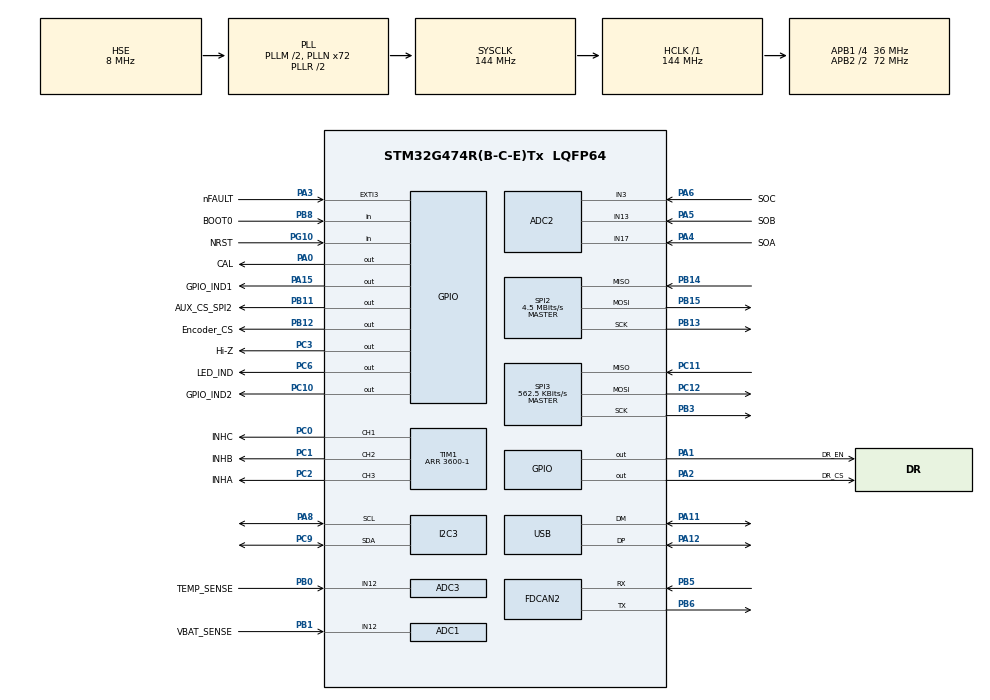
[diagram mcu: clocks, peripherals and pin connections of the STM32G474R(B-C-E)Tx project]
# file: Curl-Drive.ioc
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ADC1.Channel-1\#ChannelRegularConversion=ADC_CHANNEL_12
ADC1.ClockPrescaler=ADC_CLOCK_ASYNC_DIV4
ADC1.ContinuousConvMode=ENABLE
ADC1.DMAContinuousRequests=ENABLE
ADC1.NbrOfConversion=1
ADC1.NbrOfConversionFlag=1
ADC1.OffsetNumber-1\#ChannelRegularConversion=ADC_OFFSET_NONE
ADC1.Rank-1\#ChannelRegularConversion=1
ADC1.SamplingTime-1\#ChannelRegularConversion=ADC_SAMPLETIME_640CYCLES_5
ADC1.master=1
ADC2.ClockPrescaler=ADC_CLOCK_ASYNC_DIV4
ADC2.EnableInjectedConversion=ENABLE
ADC2.EnableRegularConversion=DISABLE
ADC2.ExternalTrigInjecConv=ADC_EXTERNALTRIGINJEC_T1_TRGO2
ADC2.ExternalTrigInjecConvEdge=ADC_EXTERNALTRIGINJECCONV_EDGE_FALLING
ADC2.InjNumberOfConversion=3
ADC2.InjectedChannel-1\#ChannelInjectedConversion=ADC_CHANNEL_17
ADC2.InjectedChannel-2\#ChannelInjectedConversion=ADC_CHANNEL_13
ADC2.InjectedChannel-3\#ChannelInjectedConversion=ADC_CHANNEL_3
ADC2.InjectedOffsetNumber-1\#ChannelInjectedConversion=ADC_OFFSET_NONE
ADC2.InjectedOffsetNumber-2\#ChannelInjectedConversion=ADC_OFFSET_NONE
ADC2.InjectedOffsetNumber-3\#ChannelInjectedConversion=ADC_OFFSET_NONE
ADC2.InjectedRank-1\#ChannelInjectedConversion=1
ADC2.InjectedRank-2\#ChannelInjectedConversion=2
ADC2.InjectedRank-3\#ChannelInjectedConversion=3
ADC2.InjectedSamplingTime-1\#ChannelInjectedConversion=ADC_SAMPLETIME_24CYCLES_5
ADC2.InjectedSamplingTime-2\#ChannelInjectedConversion=ADC_SAMPLETIME_24CYCLES_5
ADC2.InjectedSamplingTime-3\#ChannelInjectedConversion=ADC_SAMPLETIME_24CYCLES_5
ADC2.Rank1_Channel=ADC_CHANNEL_17
ADC2.Rank2_Channel=ADC_CHANNEL_13
ADC2.Rank3_Channel=ADC_CHANNEL_3
ADC3.Channel-0\#ChannelRegularConversion=ADC_CHANNEL_12
ADC3.ClockPrescaler=ADC_CLOCK_ASYNC_DIV4
ADC3.ContinuousConvMode=ENABLE
ADC3.DMAContinuousRequests=ENABLE
ADC3.NbrOfConversionFlag=1
ADC3.OffsetNumber-0\#ChannelRegularConversion=ADC_OFFSET_NONE
ADC3.Rank-0\#ChannelRegularConversion=1
ADC3.SamplingTime-0\#ChannelRegularConversion=ADC_SAMPLETIME_640CYCLES_5
ADC3.master=1
Dma.ADC1.0.Direction=DMA_PERIPH_TO_MEMORY
Dma.ADC1.0.EventEnable=DISABLE
Dma.ADC1.0.Instance=DMA1_Channel1
Dma.ADC1.0.MemDataAlignment=DMA_MDATAALIGN_HALFWORD
Dma.ADC1.0.MemInc=DMA_MINC_DISABLE
Dma.ADC1.0.Mode=DMA_CIRCULAR
Dma.ADC1.0.PeriphDataAlignment=DMA_PDATAALIGN_HALFWORD
Dma.ADC1.0.PeriphInc=DMA_PINC_DISABLE
Dma.ADC1.0.Polarity=HAL_DMAMUX_REQ_GEN_RISING
Dma.ADC1.0.Priority=DMA_PRIORITY_LOW
Dma.ADC1.0.RequestNumber=1
Dma.ADC1.0.SignalID=NONE
Dma.ADC1.0.SyncEnable=DISABLE
Dma.ADC1.0.SyncPolarity=HAL_DMAMUX_SYNC_NO_EVENT
Dma.ADC1.0.SyncRequestNumber=1
Dma.ADC1.0.SyncSignalID=NONE
Dma.ADC3.1.Direction=DMA_PERIPH_TO_MEMORY
Dma.ADC3.1.EventEnable=DISABLE
Dma.ADC3.1.Instance=DMA1_Channel2
Dma.ADC3.1.MemDataAlignment=DMA_MDATAALIGN_HALFWORD
Dma.ADC3.1.MemInc=DMA_MINC_DISABLE
Dma.ADC3.1.Mode=DMA_CIRCULAR
Dma.ADC3.1.PeriphDataAlignment=DMA_PDATAALIGN_HALFWORD
Dma.ADC3.1.PeriphInc=DMA_PINC_DISABLE
Dma.ADC3.1.Polarity=HAL_DMAMUX_REQ_GEN_RISING
Dma.ADC3.1.Priority=DMA_PRIORITY_LOW
Dma.ADC3.1.RequestNumber=1
Dma.ADC3.1.SignalID=NONE
Dma.ADC3.1.SyncEnable=DISABLE
Dma.ADC3.1.SyncPolarity=HAL_DMAMUX_SYNC_NO_EVENT
Dma.ADC3.1.SyncRequestNumber=1
Dma.ADC3.1.SyncSignalID=NONE
Dma.Request0=ADC1
Dma.Request1=ADC3
FDCAN2.AutoRetransmission=ENABLE
FDCAN2.CalculateBaudRateNominal=500000
FDCAN2.CalculateTimeBitNominal=2000
FDCAN2.CalculateTimeQuantumNominal=20.833333333333332
FDCAN2.DataTimeSeg1=13
FDCAN2.DataTimeSeg2=10
FDCAN2.FrameFormat=FDCAN_FRAME_FD_BRS
FDCAN2.NominalPrescaler=1
FDCAN2.NominalSyncJumpWidth=19
FDCAN2.NominalTimeSeg1=76
FDCAN2.NominalTimeSeg2=19
FDCAN2.ProtocolException=ENABLE
FDCAN2.StdFiltersNbr=1
I2C3.Timing=0x60715075
Mcu.Family=STM32G4
Mcu.Name=STM32G474R(B-C-E)Tx
Mcu.Package=LQFP64
NVIC.ADC1_2_IRQn=true\:0\:0\:false\:false\:true\:true\:true\:true
NVIC.DMA1_Channel1_IRQn=true\:0\:0\:false\:false\:true\:false\:true\:true
NVIC.DMA1_Channel2_IRQn=true\:0\:0\:false\:false\:true\:false\:true\:true
NVIC.EXTI3_IRQn=true\:0\:0\:false\:false\:true\:true\:true\:true
NVIC.FDCAN2_IT0_IRQn=true\:0\:0\:false\:false\:true\:true\:true\:true
NVIC.PriorityGroup=NVIC_PRIORITYGROUP_4
NVIC.TIM3_IRQn=true\:0\:0\:false\:false\:true\:true\:true\:true
NVIC.TIM6_DAC_IRQn=true\:0\:0\:false\:false\:true\:true\:true\:true
NVIC.TIM7_DAC_IRQn=true\:0\:0\:false\:false\:true\:true\:true\:true
NVIC.USB_LP_IRQn=true\:0\:0\:false\:false\:true\:false\:true\:true
PA0.GPIO_Label=CAL
PA0.Signal=GPIO_Output
PA1.GPIO_Label=DR_EN
PA1.Signal=GPIO_Output
PA11.Mode=Device
PA11.Signal=USB_DM
PA12.Mode=Device
PA12.Signal=USB_DP
PA13.Mode=Serial_Wire
PA13.Signal=SYS_JTMS-SWDIO
PA14.Mode=Serial_Wire
PA14.Signal=SYS_JTCK-SWCLK
PA15.GPIO_Label=GPIO_IND1
PA15.Signal=GPIO_Output
PA2.GPIO_Label=DR_CS
PA2.Signal=GPIO_Output
PA3.GPIO_Label=nFAULT
PA3.GPIO_ModeDefaultEXTI=GPIO_MODE_IT_FALLING
PA3.GPIO_PuPd=GPIO_PULLUP
PA3.Signal=GPXTI3
PA4.GPIO_Label=SOA
PA4.Mode=IN17-Single-Ended
PA4.Signal=ADC2_IN17
PA5.GPIO_Label=SOB
PA5.Mode=IN13-Single-Ended
PA5.Signal=ADC2_IN13
PA6.GPIO_Label=SOC
PA6.Mode=IN3-Single-Ended
PA6.Signal=ADC2_IN3
PA8.Mode=I2C
PA8.Signal=I2C3_SCL
PB0.GPIO_Label=TEMP_SENSE
PB0.Mode=IN12-Single-Ended
PB0.Signal=ADC3_IN12
PB1.GPIO_Label=VBAT_SENSE
PB1.Mode=IN12-Single-Ended
PB1.Signal=ADC1_IN12
PB11.GPIO_Label=AUX_CS_SPI2
PB11.Signal=GPIO_Output
PB12.GPIO_Label=Encoder_CS
PB12.Signal=GPIO_Output
PB13.Mode=Full_Duplex_Master
PB13.Signal=SPI2_SCK
PB14.Mode=Full_Duplex_Master
PB14.Signal=SPI2_MISO
PB15.Mode=Full_Duplex_Master
PB15.Signal=SPI2_MOSI
PB3.Mode=Full_Duplex_Master
PB3.Signal=SPI3_SCK
PB5.GPIO_Speed=GPIO_SPEED_FREQ_VERY_HIGH
PB5.Mode=FDCAN_Activate
PB5.Signal=FDCAN2_RX
PB6.GPIO_FM6=SYSCFG_FASTMODEPLUS_PB6
PB6.GPIO_Speed=GPIO_SPEED_FREQ_VERY_HIGH
PB6.Mode=FDCAN_Activate
PB6.Signal=FDCAN2_TX
PB8-BOOT0.GPIO_Label=BOOT0
PB8-BOOT0.Signal=GPIO_Input
PC0.GPIO_Label=INHC
PC0.Signal=S_TIM1_CH1
PC1.GPIO_Label=INHB
PC1.Signal=S_TIM1_CH2
PC10.GPIO_Label=GPIO_IND2
PC10.Signal=GPIO_Output
PC11.GPIO_PuPd=GPIO_PULLUP
PC11.Mode=Full_Duplex_Master
PC11.Signal=SPI3_MISO
PC12.Mode=Full_Duplex_Master
PC12.Signal=SPI3_MOSI
PC2.GPIO_Label=INHA
PC2.Signal=S_TIM1_CH3
PC3.GPIO_Label=Hi-Z
PC3.GPIO_PuPd=GPIO_PULLUP
PC3.Signal=GPIO_Output
PC6.GPIO_Label=LED_IND
PC6.Signal=GPIO_Output
PC9.Mode=I2C
PC9.Signal=I2C3_SDA
PF0-OSC_IN.Mode=HSE-External-Oscillator
PF0-OSC_IN.Signal=RCC_OSC_IN
PF1-OSC_OUT.Mode=HSE-External-Oscillator
PF1-OSC_OUT.Signal=RCC_OSC_OUT
PG10-NRST.GPIO_Label=NRST
PG10-NRST.Signal=GPIO_Input
ProjectManager.HeapSize=0x200
ProjectManager.StackSize=0x400
ProjectManager.TargetToolchain=STM32CubeIDE
RCC.ADC12CLockSelection=RCC_ADC12CLKSOURCE_PLL
RCC.ADC12Freq_Value=36000000
RCC.ADC345CLockSelection=RCC_ADC345CLKSOURCE_PLL
RCC.ADC345Freq_Value=36000000
RCC.AHBFreq_Value=144000000
RCC.APB1CLKDivider=RCC_HCLK_DIV4
RCC.APB1Freq_Value=36000000
RCC.APB1TimFreq_Value=72000000
RCC.APB2CLKDivider=RCC_HCLK_DIV2
RCC.APB2Freq_Value=72000000
RCC.APB2TimFreq_Value=144000000
RCC.CortexFreq_Value=144000000
RCC.EXTERNAL_CLOCK_VALUE=12288000
RCC.FDCANCLockSelection=RCC_FDCANCLKSOURCE_PLL
RCC.HCLKFreq_Value=144000000
RCC.HSE_VALUE=8000000
RCC.HSI48_VALUE=48000000
RCC.HSI_VALUE=16000000
RCC.I2C3CLockSelection=RCC_I2C3CLKSOURCE_SYSCLK
RCC.LSE_VALUE=32768
RCC.PLLM=RCC_PLLM_DIV2
RCC.PLLN=72
RCC.PLLP=RCC_PLLP_DIV8
RCC.PLLQ=RCC_PLLQ_DIV6
RCC.PLLSourceVirtual=RCC_PLLSOURCE_HSE
RCC.SYSCLKFreq_VALUE=144000000
RCC.SYSCLKSource=RCC_SYSCLKSOURCE_PLLCLK
RCC.USBFreq_Value=48000000
RCC.VCOOutputFreq_Value=288000000
SH.S_TIM1_CH1.0=TIM1_CH1,PWM Generation1 CH1
SH.S_TIM1_CH2.0=TIM1_CH2,PWM Generation2 CH2
SH.S_TIM1_CH3.0=TIM1_CH3,PWM Generation3 CH3
SPI2.BaudRatePrescaler=SPI_BAUDRATEPRESCALER_8
SPI2.CLKPhase=SPI_PHASE_2EDGE
SPI2.CalculateBaudRate=4.5 MBits/s
SPI2.DataSize=SPI_DATASIZE_16BIT
SPI2.Direction=SPI_DIRECTION_2LINES
SPI2.Mode=SPI_MODE_MASTER
SPI2.VirtualType=VM_MASTER
SPI3.BaudRatePrescaler=SPI_BAUDRATEPRESCALER_64
SPI3.CLKPhase=SPI_PHASE_2EDGE
SPI3.CalculateBaudRate=562.5 KBits/s
SPI3.DataSize=SPI_DATASIZE_16BIT
SPI3.Direction=SPI_DIRECTION_2LINES
SPI3.Mode=SPI_MODE_MASTER
SPI3.VirtualType=VM_MASTER
TIM1.AutoReloadPreload=TIM_AUTORELOAD_PRELOAD_ENABLE
TIM1.AutomaticOutput=TIM_AUTOMATICOUTPUT_ENABLE
TIM1.Channel-PWM\ Generation1\ CH1=TIM_CHANNEL_1
TIM1.Channel-PWM\ Generation2\ CH2=TIM_CHANNEL_2
TIM1.Channel-PWM\ Generation3\ CH3=TIM_CHANNEL_3
TIM1.Channel-PWM\ Generation4\ No\ Output=TIM_CHANNEL_4
TIM1.CounterMode=TIM_COUNTERMODE_CENTERALIGNED1
TIM1.PeriodNoDither=3600-1
TIM1.PulseNoDither_4=0
TIM1.RepetitionCounter=0
TIM1.TIM_MasterOutputTrigger=TIM_TRGO_RESET
TIM1.TIM_MasterOutputTrigger2=TIM_TRGO2_OC4REF
TIM2.PeriodNoDither=0xffffffff
TIM2.Prescaler=8
TIM3.AutoReloadPreload=TIM_AUTORELOAD_PRELOAD_ENABLE
TIM3.PeriodNoDither=7200-1
TIM3.Prescaler=0
TIM6.AutoReloadPreload=TIM_AUTORELOAD_PRELOAD_ENABLE
TIM6.PeriodNoDither=1000-1
TIM6.Prescaler=72-1
TIM7.AutoReloadPreload=TIM_AUTORELOAD_PRELOAD_ENABLE
TIM7.PeriodNoDither=10000-1
TIM7.Prescaler=7200-1
USB_DEVICE.CLASS_NAME_FS=CDC
USB_DEVICE.VirtualMode=Cdc
USB_DEVICE.VirtualModeFS=Cdc_FS
VP_CORDIC_VS_CORDIC.Mode=CORDIC_Activate
VP_SYS_VS_DBSignals.Mode=DisableDeadBatterySignals
VP_TIM1_VS_no_output4.Mode=PWM Generation4 No Output
VP_TIM2_VS_ClockSourceINT.Mode=Internal
VP_TIM3_VS_ClockSourceINT.Mode=Internal
VP_TIM6_VS_ClockSourceINT.Mode=Enable_Timer
VP_TIM7_VS_ClockSourceINT.Mode=Enable_Timer
VP_USB_DEVICE_VS_USB_DEVICE_CDC_FS.Mode=CDC_FS
board=custom

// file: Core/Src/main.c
/* USER CODE BEGIN Header */
/**
  ******************************************************************************
  * @file           : main.c
  * @brief          : Main program body
  ******************************************************************************
  * @attention
  *
  * Copyright (c) 2025 STMicroelectronics.
  * All rights reserved.
  *
  * This software is licensed under terms that can be found in the LICENSE file
  * in the root directory of this software component.
  * If no LICENSE file comes with this software, it is provided AS-IS.
  *
  ******************************************************************************
  */
/* USER CODE END Header */
#include "main.h"
#include "adc.h"
#include "cordic.h"
#include "dma.h"
#include "fdcan.h"
#include "i2c.h"
#include "spi.h"
#include "tim.h"
#include "usb_device.h"
#include "gpio.h"

/* USER CODE BEGIN Includes */
#include "common_inc.hpp"
/* USER CODE END Includes */

void SystemClock_Config(void);

int main(void)
{

  /* MCU Configuration--------------------------------------------------------*/

  /* Reset of all peripherals, Initializes the Flash interface and the Systick. */
  HAL_Init();

  /* Configure the system clock */
  SystemClock_Config();

  /* Initialize all configured peripherals */
  MX_GPIO_Init();
  MX_DMA_Init();
  MX_ADC2_Init();
  MX_TIM1_Init();
  MX_ADC1_Init();
  MX_ADC3_Init();
  MX_FDCAN2_Init();
  MX_SPI3_Init();
  MX_SPI2_Init();
  MX_I2C3_Init();
  MX_USB_Device_Init();
  MX_TIM7_Init();
  MX_TIM2_Init();
  MX_TIM6_Init();
  MX_CORDIC_Init();
  MX_TIM3_Init();
  /* USER CODE BEGIN 2 */

//  Main();
  main_app();

  /* USER CODE END 2 */

  /* Infinite loop */
  while (1)
  {

  }
}

void SystemClock_Config(void)
{
  RCC_OscInitTypeDef RCC_OscInitStruct = {0};
  RCC_ClkInitTypeDef RCC_ClkInitStruct = {0};

  /** Configure the main internal regulator output voltage
  */
  HAL_PWREx_ControlVoltageScaling(PWR_REGULATOR_VOLTAGE_SCALE1);

  /** Initializes the RCC Oscillators according to the specified parameters
  * in the RCC_OscInitTypeDef structure.
  */
  RCC_OscInitStruct.OscillatorType = RCC_OSCILLATORTYPE_HSE;
  RCC_OscInitStruct.HSEState = RCC_HSE_ON;
  RCC_OscInitStruct.PLL.PLLState = RCC_PLL_ON;
  RCC_OscInitStruct.PLL.PLLSource = RCC_PLLSOURCE_HSE;
  RCC_OscInitStruct.PLL.PLLM = RCC_PLLM_DIV2;
  RCC_OscInitStruct.PLL.PLLN = 72;
  RCC_OscInitStruct.PLL.PLLP = RCC_PLLP_DIV8;
  RCC_OscInitStruct.PLL.PLLQ = RCC_PLLQ_DIV6;
  RCC_OscInitStruct.PLL.PLLR = RCC_PLLR_DIV2;
  if (HAL_RCC_OscConfig(&RCC_OscInitStruct) != HAL_OK)
  {
    Error_Handler();
  }

  /** Initializes the CPU, AHB and APB buses clocks
  */
  RCC_ClkInitStruct.ClockType = RCC_CLOCKTYPE_HCLK|RCC_CLOCKTYPE_SYSCLK
                              |RCC_CLOCKTYPE_PCLK1|RCC_CLOCKTYPE_PCLK2;
  RCC_ClkInitStruct.SYSCLKSource = RCC_SYSCLKSOURCE_PLLCLK;
  RCC_ClkInitStruct.AHBCLKDivider = RCC_SYSCLK_DIV1;
  RCC_ClkInitStruct.APB1CLKDivider = RCC_HCLK_DIV4;
  RCC_ClkInitStruct.APB2CLKDivider = RCC_HCLK_DIV2;

  if (HAL_RCC_ClockConfig(&RCC_ClkInitStruct, FLASH_LATENCY_4) != HAL_OK)
  {
    Error_Handler();
  }
}

void Error_Handler(void)
{
  __disable_irq();
  while (1)
  {
  }
}
